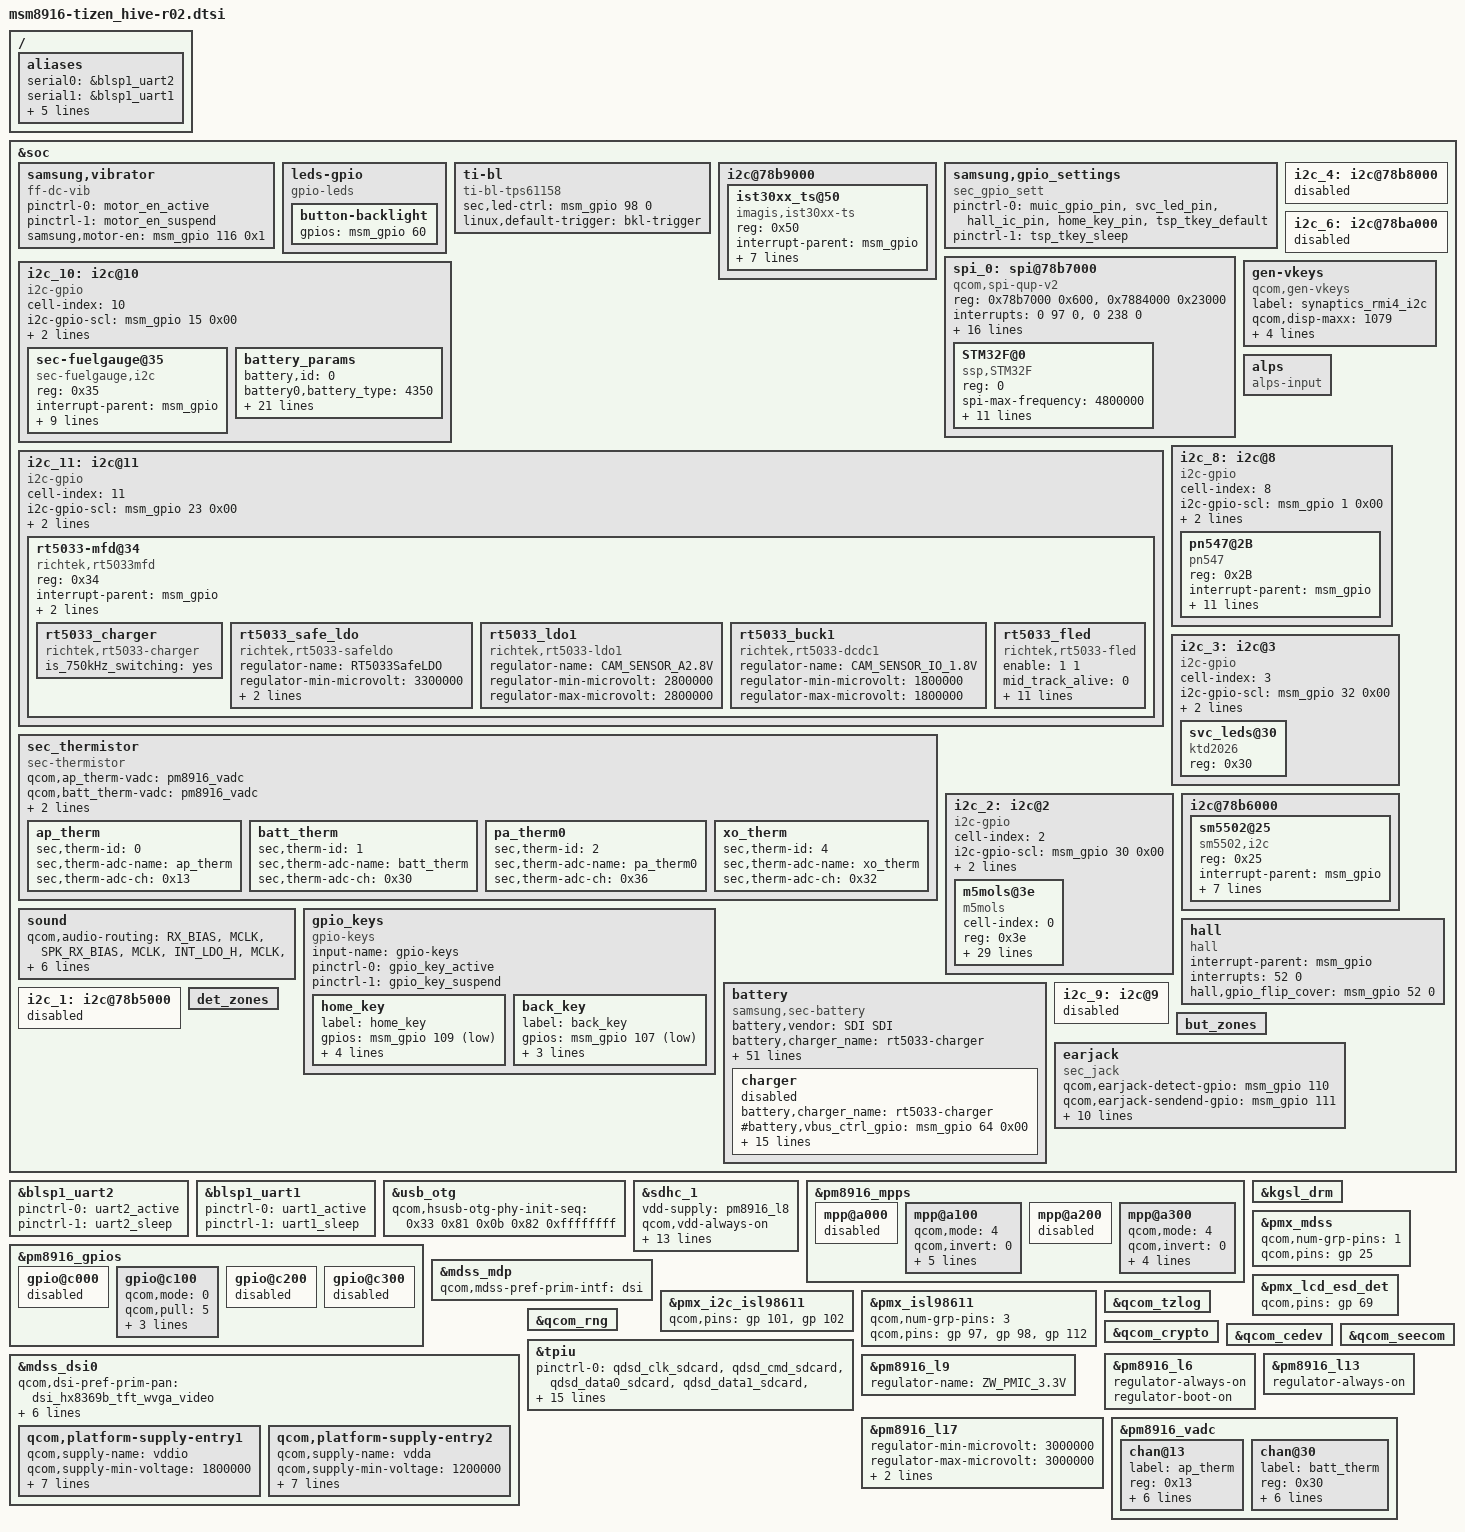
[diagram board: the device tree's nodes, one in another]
/* Copyright (c) 2015, The Linux Foundation. All rights reserved.
 *
 * This program is free software; you can redistribute it and/or modify
 * it under the terms of the GNU General Public License version 2 and
 * only version 2 as published by the Free Software Foundation.
 *
 * This program is distributed in the hope that it will be useful,
 * but WITHOUT ANY WARRANTY; without even the implied warranty of
 * MERCHANTABILITY or FITNESS FOR A PARTICULAR PURPOSE.  See the
 * GNU General Public License for more details.
 */

#include "msm8916.dtsi"
#include "msm8916-pinctrl-tizen-hive-r02.dtsi"
#include "msm8916-w1-r01.dtsi"
#include "msm8916-camera-hive.dtsi"
#include "msm8916-camera-sensor-cdp-hive.dtsi"

/ {
	aliases {
		serial0 = &blsp1_uart2;
		serial1 = &blsp1_uart1;

		/*i2c-gpio bus_id*/
		i2c8 = &i2c_8;
		i2c3 = &i2c_3;
		i2c10 = &i2c_10;
		i2c11 = &i2c_11;
		/*spi-gpio bus_id*/
		spi2 = &spi_0;
		};
};

&soc {
	samsung,vibrator {
		pinctrl-names = "tlmm_motor_en_active","tlmm_motor_en_suspend";
		pinctrl-0 = <&motor_en_active>;
		pinctrl-1 = <&motor_en_suspend>;
		compatible = "ff-dc-vib";
		samsung,motor-en = <&msm_gpio 116 0x1>;
		status = "ok";
	};

	leds-gpio{
		compatible = "gpio-leds";
		button-backlight{
			gpios = <&msm_gpio 60 0>;
			status = "ok";
		};
	};

	ti-bl {
		compatible = "ti-bl-tps61158";
		sec,led-ctrl = <&msm_gpio 98 0>;
		linux,default-trigger = "bkl-trigger";
	};

	i2c@78b9000 { /* BLSP1 QUP5 */
		status = "ok";
		ist30xx_ts@50 {
			compatible = "imagis,ist30xx-ts";
			reg = <0x50>;
			interrupt-parent = <&msm_gpio>;
			interrupts = <13 0>;
			pinctrl-names = "tsp_int_active", "tsp_en_gpio_active", "tsp_en_gpio_suspend";
			pinctrl-0 = <&int_active>;
			pinctrl-1 = <&tsp_en_active>;
			pinctrl-2 = <&tsp_en_suspend>;

			vdd_en-gpio = <&msm_gpio 20 0x01>;
			imagis,irq-gpio = <&msm_gpio 13 0x00>;
			imagis,i2c-pull-up = <1>;
		};
	};

	samsung,gpio_settings{
		compatible = "sec_gpio_sett";
		pinctrl-names = "sec_gpio_active","sec_gpio_suspend";
		pinctrl-0 = <&muic_gpio_pin &svc_led_pin &hall_ic_pin &home_key_pin &tsp_tkey_default>;
		pinctrl-1 = <&tsp_tkey_sleep>;
	};

	spi_0: spi@78b7000 { /* BLSP1 QUP3 */
		compatible = "qcom,spi-qup-v2";
		#address-cells = <1>;
		#size-cells = <0>;
		reg-names = "spi_physical", "spi_bam_physical";
		reg = <0x78b7000 0x600>, <0x7884000 0x23000>;
		interrupt-names = "spi_irq", "spi_bam_irq";
		interrupts = <0 97 0>, <0 238 0>;
		spi-max-frequency = <50000000>;

		qcom,gpio-mosi = <&msm_gpio 8 0>;
		qcom,gpio-miso = <&msm_gpio 9 0>;
		qcom,gpio-clk  = <&msm_gpio 11 0>;
		qcom,gpio-cs0  = <&msm_gpio 10 0>;

		pinctrl-names = "default", "sleep";
		pinctrl-0 = <&spi0_default &spi0_cs0_active>;
		pinctrl-1 = <&spi0_sleep &spi0_cs0_sleep>;
		clock-names = "iface_clk", "core_clk";
		clocks = <&clock_gcc clk_gcc_blsp1_ahb_clk>, <&clock_gcc clk_gcc_blsp1_qup3_spi_apps_clk>;
		qcom,infinite-mode = <0>;
		qcom,use-bam;
		qcom,use-pinctrl;
		qcom,ver-reg-exists;
		qcom,bam-consumer-pipe-index = <8>;
		qcom,bam-producer-pipe-index = <9>;
		qcom,master-id = <86>;
		status = "ok";

		STM32F@0 {
			compatible = "ssp,STM32F";
			reg = <0>;

			spi-max-frequency = <4800000>;
			interrupt-parent = <&msm_gpio>;
			interrupts = <106 0>;

			ssp,mcu_int1-gpio = <&msm_gpio 115 0x00>;
			ssp,mcu_int2-gpio = <&msm_gpio 113 0x00>;
			ssp,ap_int-gpio = <&msm_gpio 111 0x00>;
			ssp,rst-gpio = <&msm_gpio 110 0x00>;
			ssp,acc-position = <1>;
			ssp,mag-position = <6>;
			ssp,ap-rev=<2>;
			ssp,fw_name = "ssp_hive.fw";
			ssp,ums_fw_name = "ssp_stm.bin";
			//ssp,mcu_vdd-gpio = <&msm_gpio 74 0x00>;
			status = "ok";
		};
	};

	i2c_4: i2c@78b8000 { /* BLSP1 QUP4 */
		status="disable";
	};

	i2c_10:i2c@10 {
		cell-index = <10>;
		compatible = "i2c-gpio";
		i2c-gpio-scl = <&msm_gpio 15 0x00>;
		i2c-gpio-sda = <&msm_gpio 14 0x00>;
		i2c-gpio,delay-us = <2>;
		#address-cells = <1>;
		#size-cells = <0>;

		sec-fuelgauge@35{
			compatible = "sec-fuelgauge,i2c";
			reg = <0x35>;
			interrupt-parent = <&msm_gpio>;
			pinctrl-names = "default";
			pinctrl-0 = <&fg_i2c_active &fuel_int_active>;
			fuelgauge,irqf = "IRQF_TRIGGER_FALLING + IRQF_ONESHOT + IRQF_NO_SUSPEND";
			fuelgauge,fuel_int = <&msm_gpio 121 0x1>;
			fuelgauge,capacity_max = <1000>;
			fuelgauge,capacity_max_margin = <50>;
			fuelgauge,capacity_min = <0>;
			fuelgauge,capacity_calculation_type = <0x17>;
			fuelgauge,fuel_alert_soc = <1>;
		};

		battery_params {
			battery,id = <0>; /* -1 means auto, detected by F/G */
			battery0,battery_type = <4350>; /* 4200 4350 4400 */
			battery0,vg_comp_interpolation_order = <1 1>; /* necessary */
			battery0,vg_comp_idle_size = <3 4>; /* necessary */
			battery0,vg_comp_idle_data = <3200	(-1)	35	20	25	65
							3735	(-1)	35	20	25	65
							3853	(-1)	35	20	25	65
							3200	0	15	45	30	145
							3735	0	15	42	30	145
							3853	0	26	45	30	145
							3200	450	50	50	30	145
							3735	450	30	43	30	145
							3853	450	50	49	30	145
							3200	500	50	50	50	145
							3735	500	30	43	50	145
							3853	500	50	49	50	145>;
			battery0,vg_comp_normal_size = <3 4>; /* necessary */
			battery0,vg_comp_normal_data = <3200	(-1)	35	20	25	65
							3735	(-1)	35	20	25	65
							3853	(-1)	35	20	25	65
							3200	0	15	45	30	145
							3735	0	15	42	30	145
							3853	0	26	45	30	145
							3200	450	50	50	30	145
							3735	450	30	43	30	145
							3853	450	50	49	30	145
							3200	500	50	50	50	145
							3735	500	30	43	50	145
							3853	500	50	49	50	145>;
			battery0,special_case = <0>;
			battery0,offset_interpolation_order = <2 2>; /* necessary */
			battery0,offset_charging_size = <2 1>; /* m x n, m: volt or soc, n : temp */
			battery0,offset_charging_data = <0 250 0
							1030 250 0>;
			battery0,offset_discharging_size = <2 1>;
			battery0,offset_discharging_data = <0 250 0
							1030 250 0>;
			battery0,offset_special_size = <0 0>;
			battery0,offset_special_data = <0 0 0>;
			battery0,offset_low_power_size = <6 1>;
			battery0,offset_low_power_data = <0 250 (-12)
							15 250 (-5)
							19 250 (-9)
							20 250 (-10)
							100 250 0
							1000 250 0>;
			battery0,crate_idle_thres = <255>;
		};
	};

	i2c_6: i2c@78ba000 { /* BLSP1 QUP6 */
		status="disable";
	};

	i2c_11:i2c@11 {
		cell-index = <11>;
		compatible = "i2c-gpio";
		i2c-gpio-scl = <&msm_gpio 23 0x00>;
		i2c-gpio-sda = <&msm_gpio 22 0x00>;
		i2c-gpio,delay-us = <2>;
		#address-cells = <1>;
		#size-cells = <0>;

		rt5033-mfd@34{
			compatible = "richtek,rt5033mfd";
			reg = <0x34>;
			interrupt-parent = <&msm_gpio>;
			pinctrl-names = "default";
			pinctrl-0 = <&chg_i2c_active &charger_int_active>;
			rt5033,irq-gpio = <&msm_gpio 62 0x00>;

			rt5033_charger {
				compatible = "richtek,rt5033-charger";
				is_750kHz_switching = "yes";
			};

			rt5033_safe_ldo {
				compatible = "richtek,rt5033-safeldo";
				regulator-name = "RT5033SafeLDO"; /* constraints->name, change name by yourself*/
				regulator-min-microvolt = <3300000>;
				regulator-max-microvolt = <4950000>; /* if max == min then apply_uV = 1 */
				regulator-always-on = "yes";
			};

			rt5033_ldo1 {
				compatible = "richtek,rt5033-ldo1";
				regulator-name = "CAM_SENSOR_A2.8V"; /* change name by yourself */
				regulator-min-microvolt = <2800000>;
				regulator-max-microvolt = <2800000>; /* max == min then apply_uV = 1 */
			};


			rt5033_buck1 {
				compatible = "richtek,rt5033-dcdc1";
				regulator-name = "CAM_SENSOR_IO_1.8V"; /* change name by yourself */
				regulator-min-microvolt = <1800000>;
				regulator-max-microvolt = <1800000>; /* max == min then apply_uV = 1 */
			};

			rt5033_fled {
				compatible = "richtek,rt5033-fled";
				enable = <1 1>;
				mid_track_alive = <0>;
				mid_auto_track_en = <0>;
				timeout_current_level = <50>;
				strobe_current = <500>;
				strobe_timeout = <544>;
				torch_current = <63>;
				lv_protection = <3000>;
				mid_level = <4400>;
				rt5033,led1-gpio = <&msm_gpio 34 0x00>;
				rt5033,led2-gpio = <&msm_gpio 36 0x00>;
				pinctrl-names = "fled_defualt","fled_sleep";
				pinctrl-0 = <&gpio_led_default>;
				pinctrl-1 = <&gpio_led_sleep>;
			};
		};
	};

	gen-vkeys {
		compatible = "qcom,gen-vkeys";
		label = "synaptics_rmi4_i2c";
		qcom,disp-maxx = <1079>;
		qcom,disp-maxy = <1919>;
		qcom,panel-maxx = <1079>;
		qcom,panel-maxy = <2084>;
		qcom,key-codes = <158 139 172 217>;
	};

	sec_thermistor {
		compatible = "sec-thermistor";
		qcom,ap_therm-vadc = <&pm8916_vadc>;
		qcom,batt_therm-vadc = <&pm8916_vadc>;
		qcom,pa_therm0-vadc = <&pm8916_vadc>;
		qcom,xo_therm-vadc = <&pm8916_vadc>;
		ap_therm {
			sec,therm-id = <0>; /* SEC_THERM_AP */
			sec,therm-adc-name = "ap_therm";
			sec,therm-adc-ch = <0x13>; /* MPP4 */
		};
		batt_therm {
			sec,therm-id = <1>; /* SEC_THERM_BATTERY */
			sec,therm-adc-name = "batt_therm";
			sec,therm-adc-ch = <0x30>; /* LR_MUX1_BATT_THERM */
		};
		pa_therm0 {
			sec,therm-id = <2>; /* SEC_THERM_PAM0 */
			sec,therm-adc-name = "pa_therm0";
			sec,therm-adc-ch = <0x36>;
		};
		xo_therm {
			sec,therm-id = <4>; /* SEC_THERM_XO */
			sec,therm-adc-name = "xo_therm";
			sec,therm-adc-ch = <0x32>;
		};
	};

	alps {
		compatible = "alps-input";
	};

	i2c_8: i2c@8 {
		cell-index = <8>;
		compatible = "i2c-gpio";
		i2c-gpio-scl = <&msm_gpio 1 0x00>;
		i2c-gpio-sda = <&msm_gpio 0 0x00>;
		#address-cells = <1>;
		#size-cells = <0>;
		i2c-gpio,delay-us = <2>;
		pn547@2B {
			compatible = "pn547";
			reg = <0x2B>;
			interrupt-parent = <&msm_gpio>;
			interrupts = <21 0>;
			pinctrl-names = "nfc_active","nfc_suspend";
			pinctrl-0 = <&nfc_int_active &nfc_enable_active &nfc_firmware_active &nfc_i2c_active>;
			pinctrl-1 = <&nfc_int_suspend &nfc_enable_suspend &nfc_firmware_suspend &nfc_i2c_suspend>;
			pn547,firm-gpio = <&msm_gpio 49 0x00>;
			pn547,ven-gpio = <&msm_gpio 20 0x00>;
			pn547,irq-gpio = <&msm_gpio 21 0x01>;
			nfc_ldo-supply = <&pm8916_l14>;
			clocks = <&clock_rpm clk_bb_clk2_pin>;
			clock-names = "nfc_clock";
		};
	};

	i2c_3: i2c@3 {
		cell-index = <3>;
		compatible = "i2c-gpio";
		i2c-gpio-scl = <&msm_gpio 32 0x00>;
		i2c-gpio-sda = <&msm_gpio 31 0x00>;
		i2c-gpio,delay-us = <2>;
		#address-cells = <1>;
		#size-cells = <0>;

		svc_leds@30{
			compatible = "ktd2026";
			reg = <0x30>;
		};
	};

	i2c_2: i2c@2 {
		cell-index = <2>;
		compatible = "i2c-gpio";
		i2c-gpio-scl = <&msm_gpio 30 0x00>;
		i2c-gpio-sda = <&msm_gpio 29 0x00>;
		i2c-gpio,delay-us = <2>;
		#address-cells = <1>;
		#size-cells = <0>;
		m5mols@3e{
			compatible = "m5mols";
			cell-index = <0>;
			reg = <0x3e>;
			qcom,csiphy-sd-index = <0>;
			qcom,csid-sd-index = <0>;
			qcom,sensor-name = "m5mols";
			qcom,mount-angle = <90>;
			cam_vio-supply = <&pm8916_l16>;
			qcom,cam-vreg-name = "cam_vdig", "cam_vio", "cam_vana";
			qcom,cam-vreg-type = <1 0 1>;
			qcom,cam-vreg-min-voltage = <0 1800000 0>;
			qcom,cam-vreg-max-voltage = <0 1800000 0>;
			qcom,cam-vreg-op-mode = <200000 0 80000>;
			pinctrl-names = "cam_default", "cam_suspend";
			pinctrl-0 = <&cam_sensor_mclk0_default &cam_sensor_rear_default>;
			pinctrl-1 = <&cam_sensor_mclk0_sleep &cam_sensor_rear_sleep>;
			gpios = <&msm_gpio 26 0>,
				  <&msm_gpio 33 0>,
				  <&msm_gpio 35 0>;
			qcom,gpio-vdig = <1>;
			qcom,gpio-reset = <2>;
			qcom,gpio-req-tbl-num = <0 1 2>;
			qcom,gpio-req-tbl-flags = <1 0 0>;
			qcom,gpio-req-tbl-label = "CAMIF_MCLK",
				"CAM_VDIG",
				"CAM_RESET";
			qcom,sensor-position = <0>;
			qcom,sensor-mode = <0>;
			clocks = <&clock_gcc clk_mclk0_clk_src>,
				   <&clock_gcc clk_gcc_camss_mclk0_clk>;
			clock-names = "cam_src_clk", "cam_clk";
			interrupt-parent = <&msm_gpio>;
			interrupts= <38 0>;
			m5mols,irq-gpio = <&msm_gpio 38 0x00>;
		};
	};

	i2c@78b6000 { /* BLSP1 QUP2 */
		status = "ok";
		sm5502@25{
			compatible = "sm5502,i2c";
			reg = <0x25>;
			interrupt-parent = <&msm_gpio>;
			interrupts= <12 0>;
			sm5502,irq-gpio = <&msm_gpio 12 0x00>;
			sm5502,gpio-sda = <&msm_gpio 6 0x00>;
			sm5502,gpio-scl = <&msm_gpio 7 0x00>;
			sm5502,uarton-gpio = <&msm_gpio 114 0x00>;
			pinctrl-names = "sm5502_i2c_active","sm5502_i2c_suspend";
			pinctrl-0 = <&muic_i2c_active &muic_int_pin>;
			pinctrl-1 = <&muic_i2c_suspend &muic_int_pin>;
		};
	};

	/* Over-riding model specific changes */
	sound {
		qcom,audio-routing =
			"RX_BIAS", "MCLK",
			"SPK_RX_BIAS", "MCLK",
			"INT_LDO_H", "MCLK",
			"MIC BIAS External", "Handset Mic",
			"MIC BIAS External2", "Secondary Mic",
			"AMIC1", "MIC BIAS External",
			"AMIC2", "Headset Mic",
			"AMIC3", "MIC BIAS External2";
		pinctrl-names = "cdc_lines_act",
				"cdc_lines_sus";
		pinctrl-0 = <&cdc_pdm_lines_act>;
		pinctrl-1 = <&cdc_pdm_lines_sus>;
	};
};

&blsp1_uart2 {
	status = "ok";
	pinctrl-names = "default","sleep";
	pinctrl-0 = <&uart2_active>;
	pinctrl-1 = <&uart2_sleep>;
};

&blsp1_uart1 {
	status = "ok";
	pinctrl-names = "default","sleep";
	pinctrl-0 = <&uart1_active>;
	pinctrl-1 = <&uart1_sleep>;
};

&soc {
	gpio_keys {
		compatible = "gpio-keys";
		input-name = "gpio-keys";
		pinctrl-names = "tlmm_gpio_key_active","tlmm_gpio_key_suspend";
		pinctrl-0 = <&gpio_key_active>;
		pinctrl-1 = <&gpio_key_suspend>;

		home_key {
			label = "home_key";
			gpios = <&msm_gpio 109 0x1>;
			linux,input-type = <1>;
			linux,code = <139>;
			gpio-key,wakeup;
			debounce-interval = <15>;
		};
		back_key {
			label = "back_key";
			gpios = <&msm_gpio 107 0x1>;
			linux,input-type = <1>;
			linux,code = <158>;
			debounce-interval = <15>;
		};
	};

	hall {
		status = "okay";
		compatible = "hall";
		interrupt-parent = <&msm_gpio>;
		interrupts = <52 0>;
		hall,gpio_flip_cover = <&msm_gpio 52 0>;

	};

	battery {
		status = "okay";
		compatible = "samsung,sec-battery";
		battery,vendor = "SDI SDI";
		battery,charger_name = "rt5033-charger";
		battery,fuelgauge_name = "sec-fuelgauge";
		battery,technology = <2>; /* POWER_SUPPLY_TECHNOLOGY_LION */

		battery,chip_vendor = "QCOM";
		battery,temp_adc_type = <1>; /* SEC_BATTERY_ADC_TYPE_AP */

		battery,polling_time = <10 30 30 30 3600>;

		battery,adc_check_count = <5>;

		battery,cable_check_type = <4>; /* SEC_BATTERY_CABLE_CHECK_PSY */
		battery,cable_source_type = <3>; /* SEC_BATTERY_CABLE_SOURCE_EXTERNAL */
		battery,event_check;
		battery,event_waiting_time = <600>;
		battery,polling_type = <1>; /* SEC_BATTERY_MONITOR_ALARM */
		battery,monitor_initial_count = <3>;

		battery,battery_check_type = <4>; /* SEC_BATTERY_CHECK_FUELGAUGE */
		battery,check_count = <0>;
		battery,check_adc_max = <1440>;
		battery,check_adc_min = <0>;

		battery,ovp_uvlo_check_type = <3>; /* SEC_BATTERY_OVP_UVLO_CHGPOLLING */

		battery,thermal_source = <2>; /* SEC_BATTERY_THERMAL_SOURCE_ADC */

		battery,temp_table_adc = <27281 27669 28178 28724 29342 30101 30912 31807 32823 33858 34950 36049 37054
			38025 38219 38448 38626 38795 38989 39229 39540 39687 39822 40523 41123 41619>;
		battery,temp_table_data = <700 650 600 550 500 450 400 350 300 250 200 150 100
			50 40 30 20 10 0 (-10) (-30) (-40) (-50) (-100) (-150) (-200)>;
		battery,temp_check_type = <2>; /* SEC_BATTERY_TEMP_CHECK_TEMP */
		battery,temp_check_count = <1>;
		battery,temp_high_threshold_event = <600>;
		battery,temp_high_recovery_event = <450>;
		battery,temp_low_threshold_event = <(-50)>;
		battery,temp_low_recovery_event = <0>;
		battery,temp_high_threshold_normal = <600>;
		battery,temp_high_recovery_normal = <450>;
		battery,temp_low_threshold_normal = <(-50)>;
		battery,temp_low_recovery_normal = <0>;
		battery,temp_high_threshold_lpm = <600>;
		battery,temp_high_recovery_lpm = <450>;
		battery,temp_low_threshold_lpm = <(-50)>;
		battery,temp_low_recovery_lpm = <0>;
		battery,full_check_type = <7>; /* SEC_BATTERY_FULLCHARGED_CHGPSY */
		battery,full_check_type_2nd = <3>; /* SEC_BATTERY_FULLCHARGED_TIME */
		battery,full_check_count = <1>;
		battery,chg_gpio_full_check = <0>;
		battery,chg_polarity_full_check = <1>;

		/* SEC_BATTERY_FULL_CONDITION_SOC |
		   SEC_BATTERY_FULL_CONDITION_NOTIMEFULL |
		   SEC_BATTERY_FULL_CONDITION_VCELL */
		battery,full_condition_type = <13>;
		battery,full_condition_soc = <95>;
		battery,full_condition_vcell = <4300>;

		battery,recharge_check_count = <1>;
		battery,recharge_condition_type = <4>; /* SEC_BATTERY_RECHARGE_CONDITION_VCELL */
		battery,recharge_condition_soc = <98>;
		battery,recharge_condition_vcell = <4300>;

		battery,charging_total_time = <21600>;
		battery,recharging_total_time = <5400>;
		battery,charging_reset_time = <0>;

		charger{
			status = "disable";
			/* Charger */
			battery,charger_name = "rt5033-charger";
			#battery,vbus_ctrl_gpio = <&msm_gpio 64 0x00>;
			battery,chg_gpio_en = <0>;
			battery,chg_polarity_en = <0>;
			battery,chg_gpio_status = <0>;
			battery,chg_polarity_status = <0>;
			battery,chg_float_voltage = <4350>;
			battery,ovp_uvlo_check_type = <3>; /* SEC_BATTERY_OVP_UVLO_CHGPOLLING */
			battery,full_check_type = <2>; /* SEC_BATTERY_FULLCHARGED_FG_CURRENT */

			battery,input_current_limit = <1500 500 500 1500 500 1000 1000 500 500 1000 1000 1500 1500 500 1000 500 700 1000 500 1000 1500 500 500>;
			battery,fast_charging_current = <1500 0 500 1500 500 1000 1000 500 0 1200 1500 1500 1500 (-1) 1300 500 800 1300 500 1000 1500 0 0>;
			battery,full_check_current_1st = <200 0 200 200 200 200 200 200 0 200 200 200 200 0 200 200 200 200 200 200 200 0 0>;
			battery,full_check_current_2nd = <2400 0 2400 2400 2400 2400 2400 2400 0 2400 2400 2400 2400 0 2400 2400 2400 2400 2400 2400 2400 0 0>;
		};
	};

	i2c_1: i2c@78b5000 { /* BLSP1 QUP1 */
		status="disable";
	};

	i2c_9:i2c@9 { /*SM5502 GPIO-I2C*/
		status="disable";
	};

	det_zones: det_zones {
		#list-det-cells = <4>;
	};

	but_zones: but_zones {
		#list-but-cells = <3>;
	};

	earjack {
		compatible = "sec_jack";
		qcom,earjack-detect-gpio = <&msm_gpio 110 0x0>;
		qcom,earjack-sendend-gpio = <&msm_gpio 111 0x0>;
		qcom,earjack-read-vadc = <&pm8916_vadc>;

		det-zones-list = <&det_zones 0 10000 10 0>,
				 <&det_zones 998 10000 10 0>,
				 <&det_zones 999 10000 10 1>,
				 <&det_zones 1820 10000 10 1>;
		but-zones-list = <&but_zones 0 0 333>,
				 <&but_zones 1 334 474>,
				 <&but_zones 2 475 841>;
		mpp-channel-scaling = <2 1 1>;
		pinctrl-names = "earjack_gpio_active","earjack_gpio_suspend";
		pinctrl-0 = <&earjack_det_act &earjack_switch_act>;
		pinctrl-1 = <&earjack_det_sus &earjack_switch_sus>;
	};
};

&usb_otg {
	qcom,hsusb-otg-phy-init-seq = <0x33 0x81 0x0b 0x82 0xffffffff>;
};

&sdhc_1 {
	vdd-supply = <&pm8916_l8>;
	qcom,vdd-always-on;
	qcom,vdd-lpm-sup;
	qcom,vdd-voltage-level = <2900000 2900000>;
	qcom,vdd-current-level = <200 400000>;

	vdd-io-supply = <&pm8916_l5>;
	qcom,vdd-io-always-on;
	qcom,vdd-io-lpm-sup;
	qcom,vdd-io-voltage-level = <1800000 1800000>;
	qcom,vdd-io-current-level = <200 60000>;

	pinctrl-names = "active", "sleep";
	pinctrl-0 = <&sdc1_clk_on &sdc1_cmd_on &sdc1_data_on>;
	pinctrl-1 = <&sdc1_clk_off &sdc1_cmd_off &sdc1_data_off>;

	qcom,nonremovable;

	status = "ok";
};

&pm8916_mpps {
	mpp@a000 { /* MPP 1 */
		/* VDD_PX */
		status = "disabled";
	};

	mpp@a100 { /* MPP 2 */
		status = "ok";
		qcom,mode = <4>; // AIN input
		qcom,invert = <0>; //No Invert
		qcom,output-type = <0>; //CMOS
		qcom,vin-sel = <2>; //PM8971_S3 1.8v
		qcom,src-sel = <0>; //MPP Constant
		qcom,ain-route = <1>; // QPNP_PIN_AIN_AMUX_CH6 = 1 for MPP2
		qcom,master-en = <1>; // Function constant
	};

	mpp@a200 { /* MPP 3 */
		/* VREF DAC */
		status = "disabled";
	};

	mpp@a300 { /* MPP 4 */
		status = "ok";
		qcom,mode = <4>; // AIN input
		qcom,invert = <0>; //No Invert
		qcom,output-type = <0>; //CMOS
		qcom,src-sel = <0>; //MPP Constant
		qcom,ain-route = <3>; // QPNP_PIN_AIN_AMUX_CH8 = 3 for MPP4
		qcom,master-en = <1>; // Function constant
	};
};

&pm8916_gpios {
	gpio@c000 { /* GPIO 1 */
		/* Battery UICC Alarm */
		status = "disabled";
	};

	gpio@c100 { /* GPIO 2 */
		/* NFC_CLK_REQ */
		qcom,mode = <0>; /* QPNP_PIN_MODE_DIG_IN */
		qcom,pull = <5>; /* QPNP_PIN_PULL_NO */
		qcom,vin-sel = <2>; /* QPNP_PIN_VIN2 */
		qcom,src-sel = <2>; /* QPNP_PIN_SEL_FUNC_1 */
		qcom,master-en = <1>;
	};

	gpio@c200 { /* GPIO 3 */
		/* External regulator control for WTR */
		status = "disabled";
	};

	gpio@c300 { /* GPIO 4 */
		/* External regulator control for APC */
		status = "disabled";
	};
};

&kgsl_drm {
	status="okay";
};

#include "dsi-panel-hx8369b-tft-wvga-video.dtsi"

&mdss_mdp {
	qcom,mdss-pref-prim-intf = "dsi";
};


&pmx_mdss {
	qcom,num-grp-pins = <1>;
	qcom,pins = <&gp 25>;
};

&pmx_lcd_esd_det {
	qcom,pins = <&gp 69>;
};

&pmx_i2c_isl98611 {
	qcom,pins = <&gp 101>, <&gp 102>;
};

&pmx_isl98611 {
	qcom,num-grp-pins = <3>;
	qcom,pins = <&gp 97>, <&gp 98>, <&gp 112>;
};

&mdss_dsi0 {
	qcom,dsi-pref-prim-pan = <&dsi_hx8369b_tft_wvga_video>;
	pinctrl-names = "mdss_default", "mdss_sleep";
	pinctrl-0 = <&mdss_dsi_active &lcd_flm_active>;
	pinctrl-1 = <&mdss_dsi_suspend &lcd_flm_suspend>;
	qcom,platform-reset-gpio = <&msm_gpio 25 0>;
	qcom,platform-enable-gpio = <&msm_gpio 102 0>;

	vddio-supply = <&pm8916_l6>;
	vdda-supply = <&pm8916_l2>;
	qcom,platform-supply-entry1 {
		qcom,supply-name = "vddio";
		qcom,supply-min-voltage = <1800000>;
		qcom,supply-max-voltage = <1800000>;
		qcom,supply-enable-load = <100000>;
		qcom,supply-disable-load = <100>;
		qcom,supply-pre-on-sleep = <0>;
		qcom,supply-post-on-sleep = <0>;
		qcom,supply-pre-off-sleep = <0>;
		qcom,supply-post-off-sleep = <0>;
	};
	qcom,platform-supply-entry2 {
		qcom,supply-name = "vdda";
		qcom,supply-min-voltage = <1200000>;
		qcom,supply-max-voltage = <1200000>;
		qcom,supply-enable-load = <100000>;
		qcom,supply-disable-load = <100>;
		qcom,supply-pre-on-sleep = <0>;
		qcom,supply-post-on-sleep = <0>;
		qcom,supply-pre-off-sleep = <0>;
		qcom,supply-post-off-sleep = <0>;
	};
};

&qcom_tzlog {
	status = "okay";
};

&qcom_rng {
	status = "okay";
};

&qcom_crypto {
	status = "okay";
};

&qcom_cedev {
	status = "okay";
};

&qcom_seecom {
	status = "okay";
};

/* CoreSight */
&tpiu {
	pinctrl-names = "sdcard", "trace", "swduart",
			"swdtrc", "jtag", "spmi";
	/* NIDnT */
	pinctrl-0 = <&qdsd_clk_sdcard &qdsd_cmd_sdcard
			&qdsd_data0_sdcard &qdsd_data1_sdcard
			&qdsd_data2_sdcard &qdsd_data3_sdcard>;
	pinctrl-1 = <&qdsd_clk_trace &qdsd_cmd_trace
			&qdsd_data0_trace &qdsd_data1_trace
			&qdsd_data2_trace &qdsd_data3_trace>;
	pinctrl-2 = <&qdsd_cmd_swduart &qdsd_data0_swduart
			&qdsd_data1_swduart &qdsd_data2_swduart
			&qdsd_data3_swduart>;
	pinctrl-3 = <&qdsd_clk_swdtrc &qdsd_cmd_swdtrc
			&qdsd_data0_swdtrc &qdsd_data1_swdtrc
			&qdsd_data2_swdtrc &qdsd_data3_swdtrc>;
	pinctrl-4 = <&qdsd_cmd_jtag &qdsd_data0_jtag
			&qdsd_data1_jtag &qdsd_data2_jtag
			&qdsd_data3_jtag>;
	pinctrl-5 = <&qdsd_clk_spmi &qdsd_cmd_spmi
			&qdsd_data0_spmi &qdsd_data3_spmi>;
};

&pm8916_l6 {
	regulator-always-on;
	regulator-boot-on;
};

&pm8916_l9 {
	regulator-name = "ZW_PMIC_3.3V";
};

&pm8916_l13 {
	regulator-always-on;
};

&pm8916_l17 {
	regulator-min-microvolt = <3000000>;
	regulator-max-microvolt = <3000000>;
	regulator-always-on;
	qcom,init-voltage = <3000000>;
	status = "okay";
};

&pm8916_vadc {
	chan@13 {
		label = "ap_therm";
		reg = <0x13>; // channel 19 for MPP4 , 1:1scale
		qcom,decimation = <0>;
		qcom,pre-div-channel-scaling = <0>; // 1:1scale
		qcom,calibration-type = "ratiometric";
		qcom,scale-function = <1>;
		qcom,hw-settle-time = <2>;
		qcom,fast-avg-setup = <0>;
	};

	chan@30 {
		label = "batt_therm";
		reg = <0x30>; // LR_MUX1_BATT_THERM , 1:1scale
		qcom,decimation = <0>;
		qcom,pre-div-channel-scaling = <0>; // 1:1scale
		qcom,calibration-type = "ratiometric";
		qcom,scale-function = <1>;
		qcom,hw-settle-time = <2>;
		qcom,fast-avg-setup = <0>;
	};
};
